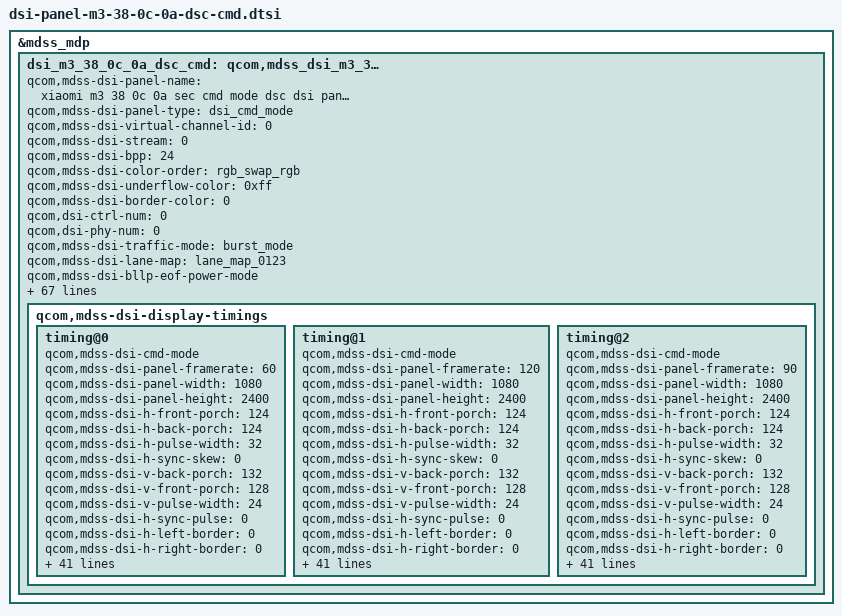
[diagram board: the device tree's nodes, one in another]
&mdss_mdp {
	dsi_m3_38_0c_0a_dsc_cmd: qcom,mdss_dsi_m3_38_0c_0a_dsc_cmd {
		qcom,mdss-dsi-panel-name = "xiaomi m3 38 0c 0a sec cmd mode dsc dsi panel";
		qcom,mdss-dsi-panel-type = "dsi_cmd_mode";
		qcom,mdss-dsi-virtual-channel-id = <0>;
		qcom,mdss-dsi-stream = <0>;
		qcom,mdss-dsi-bpp = <24>;
		qcom,mdss-dsi-color-order = "rgb_swap_rgb";
		qcom,mdss-dsi-underflow-color = <0xff>;
		qcom,mdss-dsi-border-color = <0>;
		qcom,dsi-ctrl-num = <0>;
		qcom,dsi-phy-num = <0>;

		qcom,mdss-dsi-traffic-mode = "burst_mode";
		qcom,mdss-dsi-lane-map = "lane_map_0123";
		qcom,mdss-dsi-bllp-eof-power-mode;
		qcom,mdss-dsi-bllp-power-mode;
		qcom,mdss-dsi-lane-0-state;
		qcom,mdss-dsi-lane-1-state;
		qcom,mdss-dsi-lane-2-state;
		qcom,mdss-dsi-lane-3-state;
		qcom,mdss-dsi-dma-trigger = "trigger_sw";
		qcom,mdss-dsi-mdp-trigger = "none";
		qcom,mdss-dsi-reset-sequence = <0 1>, <1 10>;
		qcom,mdss-pan-physical-width-dimension = <66>;
		qcom,mdss-pan-physical-height-dimension = <147>;
		qcom,mdss-dsi-te-pin-select = <1>;
		qcom,mdss-dsi-wr-mem-start = <0x2c>;
		qcom,mdss-dsi-wr-mem-continue = <0x3c>;
		qcom,mdss-dsi-te-dcs-command = <1>;
		qcom,mdss-dsi-te-check-enable;
		qcom,mdss-dsi-te-using-te-pin;
		qcom,mdss-dsi-tx-eot-append;
		qcom,mdss-dsi-lp11-init;

		//qcom,mdss-dsi-panel-mode-switch;

		qcom,mdss-dsi-bl-inverted-dbv;
		qcom,bl-update-flag = "delay_until_first_frame";

		qcom,mdss-dsi-dma-schedule-line = <1>;
		qcom,mdss-dsi-dma-schedule-window = <50>;

		qcom,mdss-dsi-panel-hdr-enabled;
		qcom,mdss-dsi-panel-hdr-color-primaries = <14500 15500 32000
			17000 15500 30000 8000 3000>;
		qcom,mdss-dsi-panel-peak-brightness = <4200000>;
		qcom,mdss-dsi-panel-blackness-level = <3230>;

		qcom,mdss-dsi-display-timings {
			timing@0{
				qcom,mdss-dsi-cmd-mode;
				qcom,mdss-dsi-panel-framerate = <60>;
				qcom,mdss-dsi-panel-width = <1080>;
				qcom,mdss-dsi-panel-height = <2400>;
				qcom,mdss-dsi-h-front-porch = <124>;
				qcom,mdss-dsi-h-back-porch = <124>;
				qcom,mdss-dsi-h-pulse-width = <32>;
				qcom,mdss-dsi-h-sync-skew = <0>;
				qcom,mdss-dsi-v-back-porch = <132>;
				qcom,mdss-dsi-v-front-porch = <128>;
				qcom,mdss-dsi-v-pulse-width = <24>;
				qcom,mdss-dsi-h-sync-pulse = <0>;
				qcom,mdss-dsi-h-left-border = <0>;
				qcom,mdss-dsi-h-right-border = <0>;
				qcom,mdss-dsi-v-top-border = <0>;
				qcom,mdss-dsi-v-bottom-border = <0>;
				qcom,mdss-dsi-panel-clockrate = <1100000000>;
				qcom,mdss-dsi-panel-jitter = <0x5 0x1>;
				qcom,mdss-mdp-transfer-time-us = <7300>;

				qcom,mdss-dsi-on-command = [
					/* DSC Setting */
					39 00 00 00 00 00 5A 9E 11 00 00 89 30
					   80 09 D8 04 38 00 28 02 1C 02 1C 02
					   00 02 3B 00 20 03 92 00 07 00 0E 02
					   E0 02 8B 18 00 10 F0 03 0C 20 00 06
					   0B 0B 33 0E 1C 2A 38 46 54 62 69 70
					   77 79 7B 7D 7E 01 02 01 00 09 40 09
					   BE 19 FC 19 FA 19 F8 1A 38 1A 78 1A
					   B6 2A B6 2A F4 2A F4 4B 34 63 74 00
					/* Compression Enable */
					15 00 00 00 00 00 02 9D 01
					/* Sleep Out */
					05 00 00 00 78 00 02 11 00
					/* Common Setting */
					/* TE(Vsync) On */
					15 00 00 00 00 00 02 35 00
					/* CASET/PASET Setting 1080*2400 */
					39 00 00 40 00 00 05 2A 00 00 04 37
					39 00 00 00 00 00 05 2B 00 00 09 5F
					/* Frequency Select 60.5Hz */
					39 00 00 40 00 00 03 F0 5A 5A
					15 00 00 40 00 00 02 60 08
					39 00 00 40 00 00 04 B0 00 30 BD
					15 00 00 40 00 00 02 BD 04
					39 00 00 40 00 00 04 B0 00 16 F2
					39 00 00 40 00 00 03 F2 01 70
					15 00 00 40 00 00 02 F7 0F
					39 00 00 00 00 00 03 F0 A5 A5
					/* video trim*/
					39 00 00 40 00 00 03 F0 5A 5A
					39 00 00 40 00 00 04 B0 00 36 C5
					15 00 00 40 00 00 02 C5 11
					39 00 00 40 00 00 04 B0 00 3A C5
					39 00 00 40 00 00 03 C5 3F 21
					39 00 00 40 00 00 04 B0 00 52 C5
					39 00 00 40 00 00 03 C5 3F 21
					39 00 00 00 00 00 03 F0 A5 A5
					/* Dimming Setting*/
					39 00 00 40 00 00 03 F0 5A 5A
					39 00 00 40 00 00 04 B0 00 0D 94
					15 00 00 40 00 00 02 94 20
					15 00 00 40 00 00 02 53 28
					39 00 00 40 00 00 03 51 00 00
					15 00 00 40 00 00 02 F7 0F
					39 00 00 00 00 00 03 F0 A5 A5
					/*Erro Flag Setting*/
					39 00 00 40 00 00 03 F0 5A 5A
					15 00 00 40 00 00 02 E5 15
					39 00 00 40 00 00 04 B0 00 3D F4
					15 00 00 40 00 00 02 F4 F0
					39 00 00 40 00 00 05 ED 43 49 42 03
					39 00 00 00 00 00 03 F0 A5 A5
					/* DCDC Setting (SET PIN = LOW) */
					39 00 00 40 00 00 03 F0 5A 5A
					39 00 00 40 00 00 04 B0 00 0A B1
					39 00 00 40 00 00 04 B1 18 48 20
					39 00 00 00 00 00 03 F0 A5 A5
					/* SPR Setting (SET SPR = 2D) */
					39 00 00 40 00 00 03 F0 5A 5A
					39 00 00 40 00 00 04 B0 01 64 92
					39 00 00 40 00 00 02 92 70  /*set SPR 0x71:1D 0x70:2D*/
					39 00 00 00 00 00 03 F0 A5 A5
					/* flat dimming */
					39 00 00 40 00 00 03 F0 5A 5A
					39 00 00 40 00 00 04 B0 02 7E 92
					15 00 00 40 00 00 02 92 0F
					39 00 00 00 00 00 03 F0 A5 A5
					/* aod black off */
					39 00 00 40 00 00 03 F0 5A 5A
					39 00 00 40 00 00 02 BB 30
					39 00 00 40 00 00 02 F7 0F
					39 00 00 00 00 00 03 F0 A5 A5
					/* desense source on */
					39 00 00 40 00 00 03 F0 5A 5A
					39 00 00 40 00 00 04 B0 00 20 F6
					15 00 00 40 00 00 02 F6 F0
					39 00 00 00 00 00 03 F0 A5 A5
					/* recovery return */
					39 00 00 40 00 00 03 F0 5A 5A
					39 00 00 40 00 00 04 B0 00 4E 98
					39 00 00 40 00 00 04 98 00 09 80
					39 00 00 40 00 00 04 B0 00 0F F6
					15 00 00 40 00 00 02 F6 10
					39 00 00 00 14 00 02 F7 0F
					/* Display On */
					05 00 00 40 00 00 02 29 00
					39 00 00 00 00 00 03 F0 A5 A5
				];
				qcom,mdss-dsi-on-command-state = "dsi_lp_mode";

				qcom,mdss-dsi-timing-switch-command = [
					/* Frequency Select 60.5Hz */
					39 00 00 40 00 00 03 F0 5A 5A
					15 00 00 40 00 00 02 60 08
					39 00 00 40 00 00 04 B0 00 30 BD
					15 00 00 40 00 00 02 BD 04
					39 00 00 40 00 00 04 B0 00 16 F2
					39 00 00 40 00 00 03 F2 01 70
					15 00 00 40 00 00 02 F7 0F
					39 00 00 00 00 00 03 F0 A5 A5
				];
				qcom,mdss-dsi-timing-switch-command-state = "dsi_hs_mode";

				qcom,mdss-dsi-nolp-command = [
					39 00 00 40 00 00 03 F0 5A 5A
					15 00 00 40 00 00 02 60 08
					15 00 00 40 00 00 02 53 20
					39 00 00 40 00 00 03 51 00 00
					15 00 00 40 00 00 02 F7 0F
					39 00 00 00 22 00 03 F0 A5 A5
				];
				qcom,mdss-dsi-nolp-command-update = <0x51 3 2>;
				qcom,mdss-dsi-nolp-command-state = "dsi_lp_mode";

				qcom,compression-mode = "dsc";
				qcom,mdss-dsc-slice-height = <40>;
				qcom,mdss-dsc-slice-width = <540>;
				qcom,mdss-dsc-slice-per-pkt = <2>;
				qcom,mdss-dsc-bit-per-component = <8>;
				qcom,mdss-dsc-bit-per-pixel = <8>;
				qcom,mdss-dsc-block-prediction-enable;
			};

			timing@1{
				qcom,mdss-dsi-cmd-mode;
				qcom,mdss-dsi-panel-framerate = <120>;
				qcom,mdss-dsi-panel-width = <1080>;
				qcom,mdss-dsi-panel-height = <2400>;
				qcom,mdss-dsi-h-front-porch = <124>;
				qcom,mdss-dsi-h-back-porch = <124>;
				qcom,mdss-dsi-h-pulse-width = <32>;
				qcom,mdss-dsi-h-sync-skew = <0>;
				qcom,mdss-dsi-v-back-porch = <132>;
				qcom,mdss-dsi-v-front-porch = <128>;
				qcom,mdss-dsi-v-pulse-width = <24>;
				qcom,mdss-dsi-h-sync-pulse = <0>;
				qcom,mdss-dsi-h-left-border = <0>;
				qcom,mdss-dsi-h-right-border = <0>;
				qcom,mdss-dsi-v-top-border = <0>;
				qcom,mdss-dsi-v-bottom-border = <0>;
				qcom,mdss-dsi-panel-clockrate = <1100000000>;
				qcom,mdss-dsi-panel-jitter = <0x5 0x1>;
				qcom,mdss-mdp-transfer-time-us = <7300>;

				qcom,mdss-dsi-on-command = [
					/* DSC Setting */
					39 00 00 00 00 00 5A 9E 11 00 00 89 30
					   80 09 D8 04 38 00 28 02 1C 02 1C 02
					   00 02 3B 00 20 03 92 00 07 00 0E 02
					   E0 02 8B 18 00 10 F0 03 0C 20 00 06
					   0B 0B 33 0E 1C 2A 38 46 54 62 69 70
					   77 79 7B 7D 7E 01 02 01 00 09 40 09
					   BE 19 FC 19 FA 19 F8 1A 38 1A 78 1A
					   B6 2A B6 2A F4 2A F4 4B 34 63 74 00
					/* Compression Enable */
					15 00 00 00 00 00 02 9D 01
					/* Sleep Out */
					05 00 00 00 78 00 02 11 00
					/* Common Setting */
					/* TE(Vsync) On */
					15 00 00 00 00 00 02 35 00
					/* CASET/PASET Setting 1080*2400 */
					39 00 00 40 00 00 05 2A 00 00 04 37
					39 00 00 00 00 00 05 2B 00 00 09 5F
					/* Frequency Select 120Hz */
					39 00 00 40 00 00 03 F0 5A 5A
					15 00 00 40 00 00 02 60 00
					39 00 00 40 00 00 04 B0 00 30 BD
					15 00 00 40 00 00 02 BD 04
					39 00 00 40 00 00 04 B0 00 16 F2
					39 00 00 40 00 00 03 F2 01 70
					15 00 00 40 00 00 02 F7 0F
					39 00 00 00 00 00 03 F0 A5 A5
					/* video trim*/
					39 00 00 40 00 00 03 F0 5A 5A
					39 00 00 40 00 00 04 B0 00 36 C5
					15 00 00 40 00 00 02 C5 11
					39 00 00 40 00 00 04 B0 00 3A C5
					39 00 00 40 00 00 03 C5 3F 21
					39 00 00 40 00 00 04 B0 00 52 C5
					39 00 00 40 00 00 03 C5 3F 21
					39 00 00 00 00 00 03 F0 A5 A5
					/* Dimming Setting*/
					39 00 00 40 00 00 03 F0 5A 5A
					39 00 00 40 00 00 04 B0 00 0D 94
					15 00 00 40 00 00 02 94 20
					15 00 00 40 00 00 02 53 28
					39 00 00 40 00 00 03 51 00 00
					15 00 00 40 00 00 02 F7 0F
					39 00 00 00 00 00 03 F0 A5 A5
					/*Erro Flag Setting*/
					39 00 00 40 00 00 03 F0 5A 5A
					15 00 00 40 00 00 02 E5 15
					39 00 00 40 00 00 04 B0 00 3D F4
					15 00 00 40 00 00 02 F4 F0
					39 00 00 40 00 00 05 ED 43 49 42 03
					39 00 00 00 00 00 03 F0 A5 A5
					/* DCDC Setting (SET PIN = LOW) */
					39 00 00 40 00 00 03 F0 5A 5A
					39 00 00 40 00 00 04 B0 00 0A B1
					39 00 00 40 00 00 04 B1 18 48 20
					39 00 00 00 00 00 03 F0 A5 A5
					/* SPR Setting (SET SPR = 2D) */
					39 00 00 40 00 00 03 F0 5A 5A
					39 00 00 40 00 00 04 B0 01 64 92
					39 00 00 40 00 00 02 92 70  /*set SPR 0x71:1D 0x70:2D*/
					39 00 00 00 00 00 03 F0 A5 A5
					/* flat dimming */
					39 00 00 40 00 00 03 F0 5A 5A
					39 00 00 40 00 00 04 B0 02 7E 92
					15 00 00 40 00 00 02 92 0F
					39 00 00 00 00 00 03 F0 A5 A5
					/* aod black off */
					39 00 00 40 00 00 03 F0 5A 5A
					39 00 00 40 00 00 02 BB 30
					39 00 00 40 00 00 02 F7 0F
					39 00 00 00 00 00 03 F0 A5 A5
					/* desense source on */
					39 00 00 40 00 00 03 F0 5A 5A
					39 00 00 40 00 00 04 B0 00 20 F6
					15 00 00 40 00 00 02 F6 F0
					39 00 00 00 00 00 03 F0 A5 A5
					/* recovery return */
					39 00 00 40 00 00 03 F0 5A 5A
					39 00 00 40 00 00 04 B0 00 4E 98
					39 00 00 40 00 00 04 98 00 09 80
					39 00 00 40 00 00 04 B0 00 0F F6
					15 00 00 40 00 00 02 F6 10
					39 00 00 00 14 00 02 F7 0F
					/* Display On */
					05 00 00 40 00 00 02 29 00
					39 00 00 00 00 00 03 F0 A5 A5
				];
				qcom,mdss-dsi-on-command-state = "dsi_lp_mode";

				qcom,mdss-dsi-timing-switch-command = [
					/* Frequency Select 120Hz */
					39 00 00 40 00 00 03 F0 5A 5A
					15 00 00 40 00 00 02 60 00
					39 00 00 40 00 00 04 B0 00 30 BD
					15 00 00 40 00 00 02 BD 04
					39 00 00 40 00 00 04 B0 00 16 F2
					39 00 00 40 00 00 03 F2 01 70
					15 00 00 40 00 00 02 F7 0F
					39 00 00 00 00 00 03 F0 A5 A5
				];
				qcom,mdss-dsi-timing-switch-command-state = "dsi_hs_mode";

				qcom,mdss-dsi-nolp-command = [
					39 00 00 40 00 00 03 F0 5A 5A
					15 00 00 40 00 00 02 60 00
					15 00 00 40 00 00 02 53 20
					39 00 00 40 00 00 03 51 00 00
					15 00 00 40 00 00 02 F7 0F
					39 00 00 00 22 00 03 F0 A5 A5
				];
				qcom,mdss-dsi-nolp-command-update = <0x51 3 2>;
				qcom,mdss-dsi-nolp-command-state = "dsi_lp_mode";

				qcom,compression-mode = "dsc";
				qcom,mdss-dsc-slice-height = <40>;
				qcom,mdss-dsc-slice-width = <540>;
				qcom,mdss-dsc-slice-per-pkt = <2>;
				qcom,mdss-dsc-bit-per-component = <8>;
				qcom,mdss-dsc-bit-per-pixel = <8>;
				qcom,mdss-dsc-block-prediction-enable;
			};
			timing@2{
				qcom,mdss-dsi-cmd-mode;
				qcom,mdss-dsi-panel-framerate = <90>;
				qcom,mdss-dsi-panel-width = <1080>;
				qcom,mdss-dsi-panel-height = <2400>;
				qcom,mdss-dsi-h-front-porch = <124>;
				qcom,mdss-dsi-h-back-porch = <124>;
				qcom,mdss-dsi-h-pulse-width = <32>;
				qcom,mdss-dsi-h-sync-skew = <0>;
				qcom,mdss-dsi-v-back-porch = <132>;
				qcom,mdss-dsi-v-front-porch = <128>;
				qcom,mdss-dsi-v-pulse-width = <24>;
				qcom,mdss-dsi-h-sync-pulse = <0>;
				qcom,mdss-dsi-h-left-border = <0>;
				qcom,mdss-dsi-h-right-border = <0>;
				qcom,mdss-dsi-v-top-border = <0>;
				qcom,mdss-dsi-v-bottom-border = <0>;
				qcom,mdss-dsi-panel-clockrate = <1100000000>;
				qcom,mdss-dsi-panel-jitter = <0x5 0x1>;
				qcom,mdss-mdp-transfer-time-us = <7300>;

				qcom,mdss-dsi-on-command = [
					/* DSC Setting */
					39 00 00 00 00 00 5A 9E 11 00 00 89 30
					   80 09 D8 04 38 00 28 02 1C 02 1C 02
					   00 02 3B 00 20 03 92 00 07 00 0E 02
					   E0 02 8B 18 00 10 F0 03 0C 20 00 06
					   0B 0B 33 0E 1C 2A 38 46 54 62 69 70
					   77 79 7B 7D 7E 01 02 01 00 09 40 09
					   BE 19 FC 19 FA 19 F8 1A 38 1A 78 1A
					   B6 2A B6 2A F4 2A F4 4B 34 63 74 00
					/* Compression Enable */
					15 00 00 00 00 00 02 9D 01
					/* Sleep Out */
					05 00 00 00 78 00 02 11 00
					/* Common Setting */
					/* TE(Vsync) On */
					15 00 00 00 00 00 02 35 00
					/* CASET/PASET Setting 1080*2400 */
					39 00 00 40 00 00 05 2A 00 00 04 37
					39 00 00 00 00 00 05 2B 00 00 09 5F
					/* Frequency Select 90Hz */
					39 00 00 40 00 00 03 F0 5A 5A
					15 00 00 40 00 00 02 60 08
					39 00 00 40 00 00 04 B0 00 30 BD
					15 00 00 40 00 00 02 BD 01
					39 00 00 40 00 00 04 B0 00 16 F2
					39 00 00 40 00 00 03 F2 01 88
					15 00 00 40 00 00 02 F7 0F
					39 00 00 00 00 00 03 F0 A5 A5
					/* video trim*/
					39 00 00 40 00 00 03 F0 5A 5A
					39 00 00 40 00 00 04 B0 00 36 C5
					15 00 00 40 00 00 02 C5 11
					39 00 00 40 00 00 04 B0 00 3A C5
					39 00 00 40 00 00 03 C5 3F 21
					39 00 00 40 00 00 04 B0 00 52 C5
					39 00 00 40 00 00 03 C5 3F 21
					39 00 00 00 00 00 03 F0 A5 A5
					/* Dimming Setting*/
					39 00 00 40 00 00 03 F0 5A 5A
					39 00 00 40 00 00 04 B0 00 0D 94
					15 00 00 40 00 00 02 94 20
					15 00 00 40 00 00 02 53 28
					39 00 00 40 00 00 03 51 00 00
					15 00 00 40 00 00 02 F7 0F
					39 00 00 00 00 00 03 F0 A5 A5
					/*Erro Flag Setting*/
					39 00 00 40 00 00 03 F0 5A 5A
					15 00 00 40 00 00 02 E5 15
					39 00 00 40 00 00 04 B0 00 3D F4
					15 00 00 40 00 00 02 F4 F0
					39 00 00 40 00 00 05 ED 43 49 42 03
					39 00 00 00 00 00 03 F0 A5 A5
					/* DCDC Setting (SET PIN = LOW) */
					39 00 00 40 00 00 03 F0 5A 5A
					39 00 00 40 00 00 04 B0 00 0A B1
					39 00 00 40 00 00 04 B1 18 48 20
					39 00 00 00 00 00 03 F0 A5 A5
					/* SPR Setting (SET SPR = 2D) */
					39 00 00 40 00 00 03 F0 5A 5A
					39 00 00 40 00 00 04 B0 01 64 92
					39 00 00 40 00 00 02 92 70  /*set SPR 0x71:1D 0x70:2D*/
					39 00 00 00 00 00 03 F0 A5 A5
					/* flat dimming */
					39 00 00 40 00 00 03 F0 5A 5A
					39 00 00 40 00 00 04 B0 02 7E 92
					15 00 00 40 00 00 02 92 0F
					39 00 00 00 00 00 03 F0 A5 A5
					/* aod black off */
					39 00 00 40 00 00 03 F0 5A 5A
					39 00 00 40 00 00 02 BB 30
					39 00 00 40 00 00 02 F7 0F
					39 00 00 00 00 00 03 F0 A5 A5
					/* desense source on */
					39 00 00 40 00 00 03 F0 5A 5A
					39 00 00 40 00 00 04 B0 00 20 F6
					15 00 00 40 00 00 02 F6 F0
					39 00 00 00 00 00 03 F0 A5 A5
					/* recovery return */
					39 00 00 40 00 00 03 F0 5A 5A
					39 00 00 40 00 00 04 B0 00 4E 98
					39 00 00 40 00 00 04 98 00 09 80
					39 00 00 40 00 00 04 B0 00 0F F6
					15 00 00 40 00 00 02 F6 10
					39 00 00 00 14 00 02 F7 0F
					/* Display On */
					05 00 00 40 00 00 02 29 00
					39 00 00 00 00 00 03 F0 A5 A5
				];
				qcom,mdss-dsi-on-command-state = "dsi_lp_mode";

				qcom,mdss-dsi-timing-switch-command = [
					/* Frequency Select 90Hz */
					39 00 00 40 00 00 03 F0 5A 5A
					15 00 00 40 00 00 02 60 08
					39 00 00 40 00 00 04 B0 00 30 BD
					15 00 00 40 00 00 02 BD 01
					39 00 00 40 00 00 04 B0 00 16 F2
					39 00 00 40 00 00 03 F2 01 88
					15 00 00 40 00 00 02 F7 0F
					39 00 00 00 00 00 03 F0 A5 A5
				];
				qcom,mdss-dsi-timing-switch-command-state = "dsi_hs_mode";

				qcom,mdss-dsi-nolp-command = [
					39 00 00 40 00 00 03 F0 5A 5A
					15 00 00 40 00 00 02 60 08
					39 00 00 40 00 00 04 B0 00 30 BD
					15 00 00 40 00 00 02 BD 01
					39 00 00 40 00 00 04 B0 00 16 F2
					39 00 00 40 00 00 03 F2 01 88
					15 00 00 40 00 00 02 53 20
					39 00 00 40 00 00 03 51 00 00
					15 00 00 40 00 00 02 F7 0F
					39 00 00 00 22 00 03 F0 A5 A5
				];
				qcom,mdss-dsi-nolp-command-update = <0x51 7 2>;
				qcom,mdss-dsi-nolp-command-state = "dsi_lp_mode";

				qcom,compression-mode = "dsc";
				qcom,mdss-dsc-slice-height = <40>;
				qcom,mdss-dsc-slice-width = <540>;
				qcom,mdss-dsc-slice-per-pkt = <2>;
				qcom,mdss-dsc-bit-per-component = <8>;
				qcom,mdss-dsc-bit-per-pixel = <8>;
				qcom,mdss-dsc-block-prediction-enable;
			};
		};
	};
};

&dsi_m3_38_0c_0a_dsc_cmd {
	/* IRQF_ONESHOT | IRQF_TRIGGER_LOW */
	mi,esd-err-irq-gpio = <&tlmm 49 0x2008>;
	mi,panel-id = <0x00004D33 0x00380C00>;

	mi,local-hbm-enabled;
	mi,local-hbm-ui-ready-delay-num-frame = <3>; /* 3 frame */
	mi,fod-low-brightness-clone-threshold = <411>;
	mi,fod-low-brightness-lux-threshold = <1>;
	mi,need-fod-animal-in-normal-enabled;

	mi,mdss-dsi-panel-wp-read-command = [06 01 00 01 00 00 01 A1];
	mi,mdss-dsi-panel-wp-read-command-state = "dsi_lp_mode";
	mi,mdss-dsi-panel-wp-read-length = <4>;

	mi,panel-on-dimming-delay = <120>;
	mi,doze-hbm-dbv-level = <243>;
	mi,doze-lbm-dbv-level = <21>;
	mi,max-brightness-clone = <16383>;
	mi,mdss-dsi-fac-bl-max-level = <2047>;
	mi,mdss-fac-brightness-max-level = <2047>;
	mi,mdss-dsi-panel-dc-threshold = <450>;
	mi,dc-feature-enabled;
	mi,thermal-dimming-flag;
	mi,dc-feature-type = "crc_skip_backlight";
	mi,normal-to-aod-doze-51reg-update-value = <2453>;

	mi,flatmode-status-check-enabled;
	mi,mdss-dsi-panel-flatmode-status-offset-command = [
		39 00 00 40 00 00 03 F0 5A 5A
		39 00 00 00 00 00 04 B0 02 79 92
	];
	mi,mdss-dsi-panel-flatmode-status-offset-command-state = "dsi_lp_mode";
	mi,mdss-dsi-panel-flatmode-status-command = [
		06 01 00 01 00 00 01 92
	];
	mi,mdss-dsi-panel-flatmode-status-command-state = "dsi_lp_mode";
	mi,mdss-dsi-panel-flatmode-status-offset-end-command = [
		39 00 00 00 00 00 03 F0 A5 A5
	];
	mi,mdss-dsi-panel-flatmode-status-offset-end-command-state = "dsi_lp_mode";
	mi,mdss-dsi-panel-flatmode-status-read-length = <1>;
	mi,mdss-dsi-panel-flatmode-on-status-value = <0x25>;

	qcom,mdss-dsi-display-timings {
		/* 60 hz */
		timing@0{
			#include "dsi-panel-m3-38-0c-0a-dsc-cmd-common.dtsi"

			mi,mdss-dsi-doze-hbm-command = [
				39 00 00 20 00 00 03 51 09 95
				39 00 00 40 00 00 03 F0 5A 5A
				15 00 00 40 00 00 02 53 24
				39 00 00 40 00 00 03 51 07 FF
				15 00 00 40 00 00 02 F7 0F
				39 00 00 00 00 00 03 F0 A5 A5
			];
			mi,mdss-dsi-doze-hbm-command-update = <0x51 0 2>;
			mi,mdss-dsi-doze-hbm-command-state = "dsi_lp_mode";
			mi,mdss-dsi-doze-lbm-command = [
				39 00 00 20 00 00 03 51 09 95
				39 00 00 40 00 00 03 F0 5A 5A
				15 00 00 40 00 00 02 53 24
				39 00 00 40 00 00 03 51 00 AA
				15 00 00 40 00 00 02 F7 0F
				39 00 00 00 00 00 03 F0 A5 A5
			];
			mi,mdss-dsi-doze-lbm-command-update = <0x51 0 2>;
			mi,mdss-dsi-doze-lbm-command-state = "dsi_lp_mode";

			mi,mdss-dsi-doze-hbm-nolp-command = [
				39 00 00 40 00 00 03 F0 5A 5A
				15 00 00 40 00 00 02 60 08
				15 00 00 40 00 00 02 53 20
				39 00 00 40 00 00 03 51 00 F3
				15 00 00 40 00 00 02 F7 0F
				39 00 00 00 22 00 03 F0 A5 A5
			];
			mi,mdss-dsi-doze-lbm-nolp-command = [
				39 00 00 40 00 00 03 F0 5A 5A
				15 00 00 40 00 00 02 60 08
				15 00 00 40 00 00 02 53 20
				39 00 00 40 00 00 03 51 00 15
				15 00 00 40 00 00 02 F7 0F
				39 00 00 00 22 00 03 F0 A5 A5
			];
			mi,mdss-dsi-doze-hbm-nolp-command-state = "dsi_lp_mode";
			mi,mdss-dsi-doze-lbm-nolp-command-state = "dsi_lp_mode";
		};
		/* 120 hz */
		timing@1{
			#include "dsi-panel-m3-38-0c-0a-dsc-cmd-common.dtsi"

			mi,mdss-dsi-doze-hbm-command = [
				39 00 00 20 00 00 03 51 09 95
				39 00 00 40 00 00 03 F0 5A 5A
				15 00 00 40 00 00 02 53 24
				39 00 00 40 00 00 03 51 07 FF
				15 00 00 40 00 00 02 F7 0F
				39 00 00 00 00 00 03 F0 A5 A5
			];
			mi,mdss-dsi-doze-hbm-command-update = <0x51 0 2>;
			mi,mdss-dsi-doze-hbm-command-state = "dsi_lp_mode";
			mi,mdss-dsi-doze-lbm-command = [
				39 00 00 20 00 00 03 51 09 95
				39 00 00 40 00 00 03 F0 5A 5A
				15 00 00 40 00 00 02 53 24
				39 00 00 40 00 00 03 51 00 AA
				15 00 00 40 00 00 02 F7 0F
				39 00 00 00 00 00 03 F0 A5 A5
			];
			mi,mdss-dsi-doze-lbm-command-update = <0x51 0 2>;
			mi,mdss-dsi-doze-lbm-command-state = "dsi_lp_mode";

			mi,mdss-dsi-doze-hbm-nolp-command = [
				39 00 00 40 00 00 03 F0 5A 5A
				15 00 00 40 00 00 02 60 00
				15 00 00 40 00 00 02 53 20
				39 00 00 40 00 00 03 51 00 F3
				15 00 00 40 00 00 02 F7 0F
				39 00 00 00 22 00 03 F0 A5 A5
			];
			mi,mdss-dsi-doze-lbm-nolp-command = [
				39 00 00 40 00 00 03 F0 5A 5A
				15 00 00 40 00 00 02 60 00
				15 00 00 40 00 00 02 53 20
				39 00 00 40 00 00 03 51 00 15
				15 00 00 40 00 00 02 F7 0F
				39 00 00 00 22 00 03 F0 A5 A5
			];
			mi,mdss-dsi-doze-hbm-nolp-command-state = "dsi_lp_mode";
			mi,mdss-dsi-doze-lbm-nolp-command-state = "dsi_lp_mode";
		};
		/* 90 hz */
		timing@2{
			#include "dsi-panel-m3-38-0c-0a-dsc-cmd-common.dtsi"

			mi,mdss-dsi-doze-hbm-command = [
				39 00 00 20 00 00 03 51 09 95
				39 00 00 40 00 00 03 F0 5A 5A
				15 00 00 40 00 00 02 53 24
				39 00 00 40 00 00 03 51 07 FF
				15 00 00 40 00 00 02 F7 0F
				39 00 00 00 00 00 03 F0 A5 A5
			];
			mi,mdss-dsi-doze-hbm-command-update = <0x51 0 2>;
			mi,mdss-dsi-doze-hbm-command-state = "dsi_lp_mode";
			mi,mdss-dsi-doze-lbm-command = [
				39 00 00 20 00 00 03 51 09 95
				39 00 00 40 00 00 03 F0 5A 5A
				15 00 00 40 00 00 02 53 24
				39 00 00 40 00 00 03 51 00 F6
				15 00 00 40 00 00 02 F7 0F
				39 00 00 00 00 00 03 F0 A5 A5
			];
			mi,mdss-dsi-doze-lbm-command-update = <0x51 0 2>;
			mi,mdss-dsi-doze-lbm-command-state = "dsi_lp_mode";

			mi,mdss-dsi-doze-hbm-nolp-command = [
				39 00 00 40 00 00 03 F0 5A 5A
				15 00 00 40 00 00 02 60 00
				39 00 00 40 00 00 04 B0 00 16 F2
				39 00 00 40 00 00 03 F2 01 EA
				15 00 00 40 00 00 02 53 20
				39 00 00 40 00 00 03 51 00 F3
				15 00 00 40 00 00 02 F7 0F
				39 00 00 00 22 00 03 F0 A5 A5
			];
			mi,mdss-dsi-doze-lbm-nolp-command = [
				39 00 00 40 00 00 03 F0 5A 5A
				15 00 00 40 00 00 02 60 00
				39 00 00 40 00 00 04 B0 00 16 F2
				39 00 00 40 00 00 03 F2 01 EA
				15 00 00 40 00 00 02 53 20
				39 00 00 40 00 00 03 51 00 15
				15 00 00 40 00 00 02 F7 0F
				39 00 00 00 22 00 03 F0 A5 A5
			];
			mi,mdss-dsi-doze-hbm-nolp-command-state = "dsi_lp_mode";
			mi,mdss-dsi-doze-lbm-nolp-command-state = "dsi_lp_mode";
		};
	};
};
